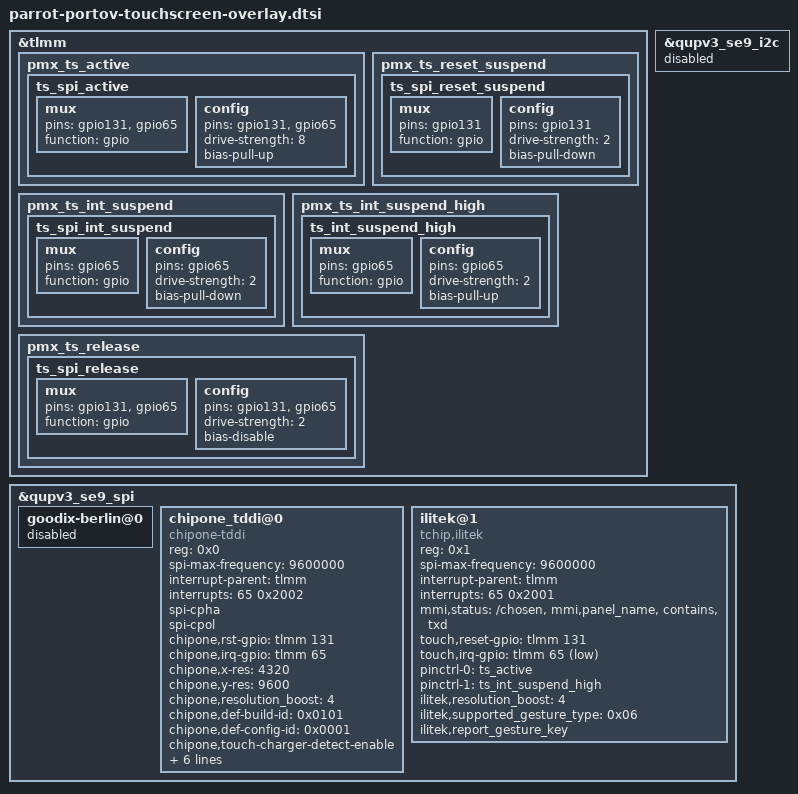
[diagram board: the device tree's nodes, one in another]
/* Copyright (c) 2021, The Linux Foundation. All rights reserved.
 *
 * This program is free software; you can redistribute it and/or modify
 * it under the terms of the GNU General Public License version 2 and
 * only version 2 as published by the Free Software Foundation.
 *
 * This program is distributed in the hope that it will be useful,
 * but WITHOUT ANY WARRANTY; without even the implied warranty of
 * MERCHANTABILITY or FITNESS FOR A PARTICULAR PURPOSE.  See the
 * GNU General Public License for more details.
 */
&tlmm {
	pmx_ts_active {
		ts_spi_active: ts_spi_active {
			mux {
				pins = "gpio131", "gpio65";
				function = "gpio";
			};

			config {
				pins = "gpio131", "gpio65";
				drive-strength = <8>;
				bias-pull-up;
			};
		};
	};

	pmx_ts_reset_suspend {
		ts_spi_reset_suspend: ts_spi_reset_suspend {
			mux {
				pins = "gpio131";
				function = "gpio";
			};

			config {
				pins = "gpio131";
				drive-strength = <2>;
				bias-pull-down;
			};
		};
	};

	pmx_ts_int_suspend {
		ts_spi_int_suspend: ts_spi_int_suspend {
			mux {
				pins = "gpio65";
				function = "gpio";
			};

			config {
				pins = "gpio65";
				drive-strength = <2>;
				bias-pull-down;
			};
		};
	};

	pmx_ts_int_suspend_high {
		ts_int_suspend_high: ts_int_suspend_high {
			mux {
				pins = "gpio65";
				function = "gpio";
			};
			config {
				pins = "gpio65";
				drive-strength = <2>;
				bias-pull-up;
			};
		};
	};

	pmx_ts_release {
		ts_spi_release: ts_spi_release {
			mux {
				pins = "gpio131", "gpio65";
				function = "gpio";
			};

			config {
				pins = "gpio131", "gpio65";
				drive-strength = <2>;
				bias-disable;
			};
		};
	};
};

&qupv3_se9_i2c {
	status = "disabled";
};

&qupv3_se9_spi {
	#address-cells = <1>;
	#size-cells = <0>;

	status = "ok";
	goodix-berlin@0 {
		status = "disabled";
	};
	chipone_tddi@0 {
		compatible = "chipone-tddi";
		reg = <0x0>;
		spi-max-frequency = <9600000>;
		interrupt-parent = <&tlmm>;
		interrupts = <65 0x2002>;
		spi-cpha;
		spi-cpol;
		chipone,rst-gpio = <&tlmm 131 0x00>;
		chipone,irq-gpio = <&tlmm 65 0x2002>;
		chipone,x-res = <4320>;
		chipone,y-res = <9600>;
		chipone,resolution_boost = <4>;
		chipone,def-build-id = <0x0101>;
		chipone,def-config-id = <0x0001>;
		chipone,touch-charger-detect-enable;
		chipone,touch-charger-detect-type = "notify"; /* notify, poll */
		chipone,touch-charger-detect-psp = "POWER_SUPPLY_PROP_ONLINE";
		chipone,touch-charger-detect-psp-poll-interval = <1000>;
		chipone,supported_gesture_type = <0x06>;
		status = "ok";
	};
	ilitek@1 {
		compatible = "tchip,ilitek";
		reg = <0x1>;
		spi-max-frequency = <9600000>;
		interrupt-parent = <&tlmm>;
		interrupts = <65 0x2001>;
		//panel = <&dsi_boe_ili9883c_656_hd_plus_120_video>;
		mmi,status = "/chosen","mmi,panel_name","contains","txd";
		touch,reset-gpio = <&tlmm 131 0x00>;
		touch,irq-gpio = <&tlmm 65 0x2001>;
		pinctrl-names = "pmx_ts_int_active","pmx_ts_int_suspend_high";
		pinctrl-0 = <&ts_active>;
		pinctrl-1 = <&ts_int_suspend_high>;
		ilitek,resolution_boost = <4>;
		ilitek,supported_gesture_type = <0x06>;
		ilitek,report_gesture_key;
		status = "ok";
	};

};

